AUTOSAR XML (schema 00051)
package /Components
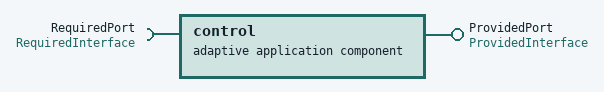
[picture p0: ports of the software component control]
  adaptive application sw component type control
    require port RequiredPort: queued-receiver-com-spec=data-element=LKAS, required-interface=RequiredInterface
    provide port ProvidedPort: provided-interface=ProvidedInterface
